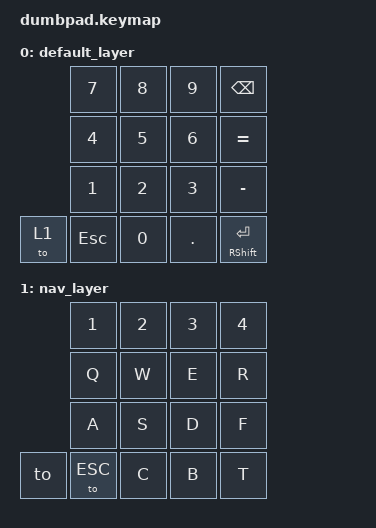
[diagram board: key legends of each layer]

/*
 * Copyright (c) 2020 The ZMK Contributors
 *
 * SPDX-License-Identifier: MIT
 */
 
#include <behaviors.dtsi>
#include <dt-bindings/zmk/keys.h>
#include <dt-bindings/zmk/bt.h>

#define DEFAULT 0
#define NAV   1
#define RAISE 2

/ {
        behaviors {
        hm: homerow_mods {
            compatible = "zmk,behavior-hold-tap";
            label = "HOMEROW_MODS";
            #binding-cells = <2>;
            tapping-term-ms = <150>;
            quick_tap_ms = <0>;
            flavor = "tap-preferred";
            bindings = <&kp>, <&kp>;
        };
    };
    keymap {
        compatible = "zmk,keymap";

        default_layer {
// ---------------------------------------
//           | 7      |  8  |  9  | bscp |
//           | 4      |  5  |  6  | EQUAL|
//           | 1      |  2  |  3  | MINUs|       
// | TO(1)   | ESC    |  0  |  .  | ENT  |
// ---------------------------------------
            bindings = <
           &kp N7    &kp N8 &kp N9  &kp BSPC
           &kp N4    &kp N5 &kp N6  &kp EQUAL
           &kp N1    &kp N2 &kp N3  &kp MINUS
    &to 1  &kp ESC   &kp N0 &kp DOT &mt RSHFT RET
            >;
           
            sensor-bindings = <&inc_dec_kp C_NEXT C_PREV>;
        };

        nav_layer {
// --------------------------------------
//           | 1     | 2   |  3   | 4   |
//           | Q     | W   |  E   | R   |
//           | A     | S   |  D   | F   |       
// | TO(0)   | ESC   | C   |  B   | T   |
// --------------------------------------
            bindings = <
           &kp 1    &kp 2   &kp 3   &kp 4
           &kp Q    &kp W   &kp E   &kp R
           &kp A    &kp S   &kp D   &kp F
    &to    &to ESC  &kp C   &kp B   &kp T
            >;
            
            sensor-bindings = <&inc_dec_kp A B>;
        };
    };
};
